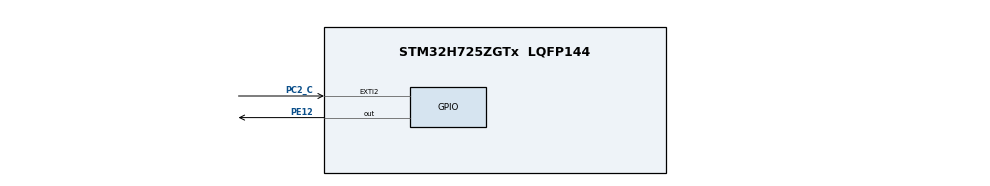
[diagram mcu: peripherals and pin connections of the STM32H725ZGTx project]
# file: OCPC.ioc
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Mcu.Family=STM32H7
Mcu.Name=STM32H725ZGTx
Mcu.Package=LQFP144
NVIC.EXTI2_IRQn=true\:0\:0\:false\:false\:true\:true\:true\:true
NVIC.PVD_AVD_IRQn=true\:0\:0\:false\:false\:true\:true\:true\:true
NVIC.PriorityGroup=NVIC_PRIORITYGROUP_4
PC2_C.Signal=GPXTI2
PE12.Signal=GPIO_Output
PH0-OSC_IN.Mode=HSE-External-Oscillator
PH0-OSC_IN.Signal=RCC_OSC_IN
PH1-OSC_OUT.Mode=HSE-External-Oscillator
PH1-OSC_OUT.Signal=RCC_OSC_OUT
ProjectManager.HeapSize=0x200
ProjectManager.StackSize=0x400
ProjectManager.TargetToolchain=STM32CubeIDE
RCC.ADCFreq_Value=129000000
RCC.APB1Freq_Value=64000000
RCC.APB2Freq_Value=64000000
RCC.APB3Freq_Value=64000000
RCC.APB4Freq_Value=64000000
RCC.CortexFreq_Value=64000000
RCC.HCLKFreq_Value=64000000
RCC.SYSCLKFreq_VALUE=64000000
RCC.USBFreq_Value=129000000
board=custom

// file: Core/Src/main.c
/* USER CODE BEGIN Header */
/**
  ******************************************************************************
  * @file           : main.c
  * @brief          : Main program body
  ******************************************************************************
  * @attention
  *
  * Copyright (c) 2023 STMicroelectronics.
  * All rights reserved.
  *
  * This software is licensed under terms that can be found in the LICENSE file
  * in the root directory of this software component.
  * If no LICENSE file comes with this software, it is provided AS-IS.
  *
  ******************************************************************************
  */
/* USER CODE END Header */
#include "main.h"

/* USER CODE BEGIN Includes */
#include"ocpc.h"

/* USER CODE END Includes */

/* USER CODE BEGIN PV */
volatile uint16_t OCPC_Status=0x0000;
volatile uint16_t OCPC_Fault_Status=0x0000;
/* USER CODE END PV */

void SystemClock_Config(void);
static void MX_GPIO_Init(void);

int main(void)
{

  /* MCU Configuration--------------------------------------------------------*/

  /* Reset of all peripherals, Initializes the Flash interface and the Systick. */
  HAL_Init();

  /* Configure the system clock */
  SystemClock_Config();

  /* Initialize all configured peripherals */
  MX_GPIO_Init();

  /* Infinite loop */
  while (1)
  {
	  /* BSP inits */
	  BSP_OCPC_Init();

	  BSP_OCPC_SetOutputStatus(BSP_OCPC_MAG, ENABLE);
	  OCPC_Status |= MAG_OCPC_SET;
	  BSP_OCPC_SetOutputStatus(BSP_OCPC_GYRO, ENABLE);
	  OCPC_Status |= GYRO_OCPC_SET;
	  BSP_OCPC_SetOutputStatus(BSP_OCPC_SUN, ENABLE);
	  OCPC_Status |= SUN_OCPC_SET;
	  BSP_OCPC_SetOutputStatus(BSP_OCPC_HB, ENABLE);
	  OCPC_Status |= HB_OCPC_SET;
	  BSP_OCPC_SetOutputStatus(BSP_OCPC_CVS, ENABLE);
	  OCPC_Status |= CVS_OCPC_SET;
	  BSP_OCPC_SetOutputStatus(BSP_OCPC_MD, ENABLE);
	  OCPC_Status |= MD_OCPC_SET;
	  BSP_OCPC_SetOutputStatus(BSP_OCPC_WDT, ENABLE);
	  OCPC_Status |= WDT_OCPC_SET;
	  BSP_OCPC_SetOutputStatus(BSP_OCPC_TS, ENABLE);
	  OCPC_Status |= TS_OCPC_SET;

	 /* void EXTI2_IRQHandler(void)
	  {
		  if (HAL_EXTI_GetPending(EXTI_HandleTypeDef *hexti, EXTI_TRIGGER_RISING_FALLING))
		  {
            if(HAL_GPIO_ReadPin(GPIOE, GPIO_PIN_12)== GPIO_PIN_RESET)

		  }
	  }*/

  }
}

void SystemClock_Config(void)
{
  RCC_OscInitTypeDef RCC_OscInitStruct = {0};
  RCC_ClkInitTypeDef RCC_ClkInitStruct = {0};

  /** Supply configuration update enable
  */
  HAL_PWREx_ConfigSupply(PWR_DIRECT_SMPS_SUPPLY);

  /** Configure the main internal regulator output voltage
  */
  __HAL_PWR_VOLTAGESCALING_CONFIG(PWR_REGULATOR_VOLTAGE_SCALE3);

  while(!__HAL_PWR_GET_FLAG(PWR_FLAG_VOSRDY)) {}

  /** Initializes the RCC Oscillators according to the specified parameters
  * in the RCC_OscInitTypeDef structure.
  */
  RCC_OscInitStruct.OscillatorType = RCC_OSCILLATORTYPE_HSI;
  RCC_OscInitStruct.HSIState = RCC_HSI_DIV1;
  RCC_OscInitStruct.HSICalibrationValue = 64;
  RCC_OscInitStruct.PLL.PLLState = RCC_PLL_NONE;
  if (HAL_RCC_OscConfig(&RCC_OscInitStruct) != HAL_OK)
  {
    Error_Handler();
  }

  /** Initializes the CPU, AHB and APB buses clocks
  */
  RCC_ClkInitStruct.ClockType = RCC_CLOCKTYPE_HCLK|RCC_CLOCKTYPE_SYSCLK
                              |RCC_CLOCKTYPE_PCLK1|RCC_CLOCKTYPE_PCLK2
                              |RCC_CLOCKTYPE_D3PCLK1|RCC_CLOCKTYPE_D1PCLK1;
  RCC_ClkInitStruct.SYSCLKSource = RCC_SYSCLKSOURCE_HSI;
  RCC_ClkInitStruct.SYSCLKDivider = RCC_SYSCLK_DIV1;
  RCC_ClkInitStruct.AHBCLKDivider = RCC_HCLK_DIV1;
  RCC_ClkInitStruct.APB3CLKDivider = RCC_APB3_DIV1;
  RCC_ClkInitStruct.APB1CLKDivider = RCC_APB1_DIV1;
  RCC_ClkInitStruct.APB2CLKDivider = RCC_APB2_DIV1;
  RCC_ClkInitStruct.APB4CLKDivider = RCC_APB4_DIV1;

  if (HAL_RCC_ClockConfig(&RCC_ClkInitStruct, FLASH_LATENCY_1) != HAL_OK)
  {
    Error_Handler();
  }
}

static void MX_GPIO_Init(void)
{
  GPIO_InitTypeDef GPIO_InitStruct = {0};

  /* GPIO Ports Clock Enable */
  __HAL_RCC_GPIOH_CLK_ENABLE();
  __HAL_RCC_GPIOC_CLK_ENABLE();
  __HAL_RCC_GPIOE_CLK_ENABLE();

  /*Configure GPIO pin Output Level */
  HAL_GPIO_WritePin(GPIOE, GPIO_PIN_12, GPIO_PIN_RESET);

  /*Configure GPIO pin : PC2 */
  GPIO_InitStruct.Pin = GPIO_PIN_2;
  GPIO_InitStruct.Mode = GPIO_MODE_IT_RISING;
  GPIO_InitStruct.Pull = GPIO_NOPULL;
  HAL_GPIO_Init(GPIOC, &GPIO_InitStruct);

  /*Configure GPIO pin : PE12 */
  GPIO_InitStruct.Pin = GPIO_PIN_12;
  GPIO_InitStruct.Mode = GPIO_MODE_OUTPUT_PP;
  GPIO_InitStruct.Pull = GPIO_NOPULL;
  GPIO_InitStruct.Speed = GPIO_SPEED_FREQ_LOW;
  HAL_GPIO_Init(GPIOE, &GPIO_InitStruct);

  /* EXTI interrupt init*/
  HAL_NVIC_SetPriority(EXTI2_IRQn, 0, 0);
  HAL_NVIC_EnableIRQ(EXTI2_IRQn);

}

void Error_Handler(void)
{
  __disable_irq();
  while (1)
  {
  }
}
